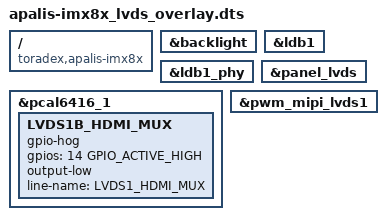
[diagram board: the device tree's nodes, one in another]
// SPDX-License-Identifier: GPL-2.0-or-later OR MIT
/*
 * Copyright 2020-2021 Toradex
 */

// LT170410 display (10 inch) with a resolution of 1280x800 pixel. This display can be ordered at Toradex.

/dts-v1/;
/plugin/;

#include <dt-bindings/gpio/gpio.h>

/ {
	compatible = "toradex,apalis-imx8x";
};

&backlight {
	status = "okay";
};

&ldb1 {
	status = "okay";
};

&ldb1_phy {
	status = "okay";
};

&panel_lvds {
	status = "okay";
};

/* On-module GPIO Expander */
&pcal6416_1 {
	/*
	 * This gpio-hog drives a muxing device. With that we can choose
	 * if LVDS1_B pins are active or if DSI signals routed to the
	 * on-module Lontium LT8912 DSI-to-HDMI bridge chip are active.
	 *
	 * output-high; muxes to DSI signals, getting Apalis HDMI1 pins active
	 * output-low; muxes to LVDS1_B signals, getting Apalis LVDS1 pins active
	 */
	 LVDS1B_HDMI_MUX {
		gpio-hog;
		gpios = <14 GPIO_ACTIVE_HIGH>;
		output-low;
		line-name = "LVDS1_HDMI_MUX";
	};
};

/* Apalis BKL1_PWM */
&pwm_mipi_lvds1 {
	status = "okay";
};
